# AC690N register map
Vendor: JieLi; Series: BR17; File version: 1.0
CPU: PI32 r1, little endian, no MPU, no FPU, 2 interrupt priority bits, 64 interrupts
Registers are 32-bit, read-write, reset 0x0 unless marked. A register's access mark holds for its fields unless they carry their own. Offsets are from the block's base; [hi:lo] are bit positions; {n}, {i} and the like mark numbered series; 'fields as' and 'values as' point back to an identical list.

## SYSCFG — System configuration and like
Base 0x00060000
0x00 CHIP_ID 16-bit ro
0x04 MODE_CON 8-bit — Operating mode control
{0x8+4i} WKUP_CON{i} 16-bit (i=0..3) — Wakeup control register {i}
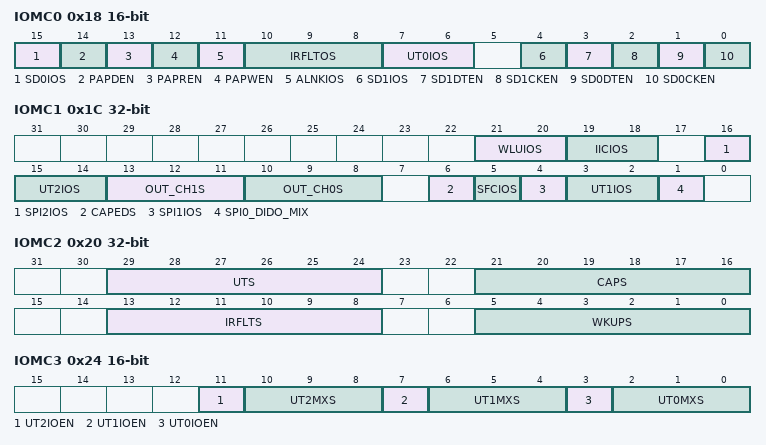
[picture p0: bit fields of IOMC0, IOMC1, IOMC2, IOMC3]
0x18 IOMC0 16-bit — IO map control register 0
  [15] SD0IOS — SD0 I/O map select
    0=Map A: CLK=PA13, CMD=PA12, DAT[0-3]={PA11/10/9/8}; 1=Map B: CLK=PA3, CLK=PA2, DAT[0-3]={PA1/0/5/4}
  [14] PAPDEN — PAP data lines enable
  [13] PAPREN — PAP read line enable
  [12] PAPWEN — PAP write line enable
  [11] ALNKIOS — ALNK I/O map select
    0=Map A: SCLK=PA9, LRCK=PA10, MCLK=PA15, DAT[0-3]={PA11/12/13/14}; 1=Map B: SCLK=PB0, LRCK=PB1, MCLK=PB6, DAT[0-3]={PB2/3/4/5}
  [10:8] IRFLTOS — IRFLT output select
    {v}=timer{v-4} (IRFLT output connected to Timer{v-4} capture) (v=4..7)
  [7:6] UT0IOS — UART0 I/O map select
    0=Map A: TX=PA5, RX=PA6; 1=Map B: TX=PB6, RX=PB7; 2=Map C: TX=PC2, RX=PC3; 3=Map D: TX=PA14, RX=PA15
  [4] SD1IOS — SD1 I/O map select
    0=Map A: CLK=PC5, CMD=PC4, DAT[0-3]={PA3/2/1/0}; 1=Map B: CLK=PB2, CMD=PB1, DAT[0-3]={PB0/3/4/5}
  [3] SD1DTEN — SD1 data lines enable
  [2] SD1CKEN — SD1 clock line enable
  [1] SD0DTEN — SD0 data lines enable
  [0] SD0CKEN — SD0 clock line enable
0x1C IOMC1 — IO map control register 1
  [21:20] WLUIOS — WLU.. wireless-uart? I/O map select
    0=Map A: TX=PA3, RX=PA4; 1=Map B: TX=PA9, RX=PA10; 2=Map C: TX=PB9, RX=PB10; 3=Map D: TX=PC4, RX=PC5
  [19:18] IICIOS — I2C I/O map select
    0=Map A: SDA=USBDP, SCL=USBDM; 1=Map B: SDA=PC4, SCL=PC5; 2=Map C: SDA=PA14, SCL=PA15; 3=Map D: SDA=PA5, SCL=PA6
  [16] SPI2IOS — SPI2 I/O map select
  [15:14] UT2IOS — UART2 I/O map select
    values as WLUIOS
  [13:11] OUT_CH1S — ch1 output select
    0=UT0_TX (UART0 TX); 1=UT1_TX (UART1 TX); 2=TMR2_PWM_OUT (Timer2 PWM output); 3=TMR3_PWM_OUT (Timer3 PWM output); 4=IRTCX32K (IRTC 32.768 khz crystal); 5=OSC_CLK (osc_clk / Oscillator clock); 6=WLU_TX; 7=PWM4_OUT (PWM4 output)
  [10:8] OUT_CH0S — ch0 output select
    0=UT0_TX (UART0 TX); 1=UT1_TX (UART1 TX); 2=TMR0_PWM_OUT (Timer0 PWM output); 3=TMR1_PWM_OUT (Timer1 PWM output); 4=RTC_OSCH (rtc_osch / IRTC high-frequency oscilllator); 5=BTOSC_CLK (btosc_clk / bluetooth oscillator); 6=PLL_12M (pll_12m / PLL 12 MHz output); 7=UT2_TX (UART2 TX)
  [6] CAPEDS — Capture mux edge selection
    0=Rising edge; 1=Falling edge
  [5] SFCIOS — SFC I/O map select
  [4] SPI1IOS — SPI1 I/O map select
  [3:2] UT1IOS — UART1 I/O map select
    0=Map A: TX=PB0, RX=PB1; 1=Map B: TX=PC0, RX=PC1; 2=Map C: TX=PA1, RX=PA2; 3=Map D: TX=USBDP, RX=USBDM
  [1] SPI0_DIDO_MIX — SPI0 DI/DO line mix
0x20 IOMC2 — IO map control register 2
  [29:24] UTS — UART input mux select
  [21:16] CAPS — Capture input mux select
  [13:8] IRFLTS — IRFLT input mux select
  [5:0] WKUPS — Wakeup input mux select
0x24 IOMC3 16-bit — IO map control register 3
  [11] UT2IOEN — UART2 I/O enable
  [10:8] UT2MXS — UART2 input mux select
  [7] UT1IOEN — UART1 I/O enable
  [6:4] UT1MXS — UART1 input mux select
  [3] UT0IOEN — UART0 I/O enable
  [2:0] UT0MXS — UART0 input mux select
0x40 PWR_CON 16-bit — Power control register
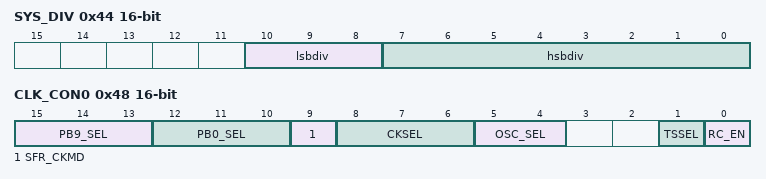
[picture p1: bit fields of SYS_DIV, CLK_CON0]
0x44 SYS_DIV 16-bit — System clock divider
  [10:8] lsbdiv — lsb_clk divider (from hsb_clk)
  [7:0] hsbdiv — hsb_clk divider (from org_clk)
0x48 CLK_CON0 16-bit — Clock control register 0
  [15:13] PB9_SEL — PB9 clock output
    0=disabled (No clock output); 1=FM_LO_D2 (FM local-oscillator divided by 2); 2=PLL_RFI_CLK (pll_rfi_clk output); 3=PLL_192M (pll_192m output); 4=BT_LO_D32 (Bluetooth local-oscillator divided by 32); 5=WL_CLK (wl_clk output); 6=APC_CLK (apc_clk output); 7=RCCL_CLK (?? rccl_clk output)
  [12:10] PB0_SEL — PB0 clock output
    0=disabled (No clock output); 1=LSB_CLK (lsb_clk output); 2=BTOSC_CLK (btosc_clk output); 3=RTOSH_CLK (rtosh_clk output); 4=RC_CLK (rc_clk output); 5=HSB_CLK (hsb_clk output); 6=RTOSL_CLK (rtosl_clk output); 7=PLL_SYS_CLK (pll_sys_clk output)
  [9] SFR_CKMD
  [8:6] CKSEL — clock select
    0=RC_CLK (Use rc_clk (RC oscillator)); 4=BTOSC_CLK (Use btosc_clk (Bluetooth oscillator)); 5=RTOSH_CLK (Use rtosh_clk (RTC high-freq oscillator)); 6=RTOSL_CLK (Use rtosl_clk (RTC low-freq oscillator)); 7=PLL_CLK (Use pll_clk (or pll_sys_clk))
  [5:4] OSC_SEL — osc_clk selection
    0=BTOSC_CLK (Use btosc_clk (Bluetooth oscillator)); 1=RTOSH_CLK (Use rtosh_clk (RTC high-freq oscillator)); 2=RTOSL_CLK (Use rtosl_clk (RTC low-freq oscillator)); 3=TEST_MODE (Use test mode clock)
  [1] TSSEL — test clock select
  [0] RC_EN — RC oscillator enable
0x4C CLK_CON1 — Clock control register 1
0x50 CLK_CON2 — Clock control register 2
0x80 PLL_CON — PLL control register
0x84 LDO_CON — LDO control register
0x88 LVD_CON 16-bit — Low Voltage Detector control register
0x8C WDT_CON 8-bit — Watchdog control register
0x90 OSA_CON 8-bit — OSA control register
0x94 EFUSE_CON 16-bit — eFuse control register
